VERSION ""

NS_ :

BS_:

BU_: Charger BMS

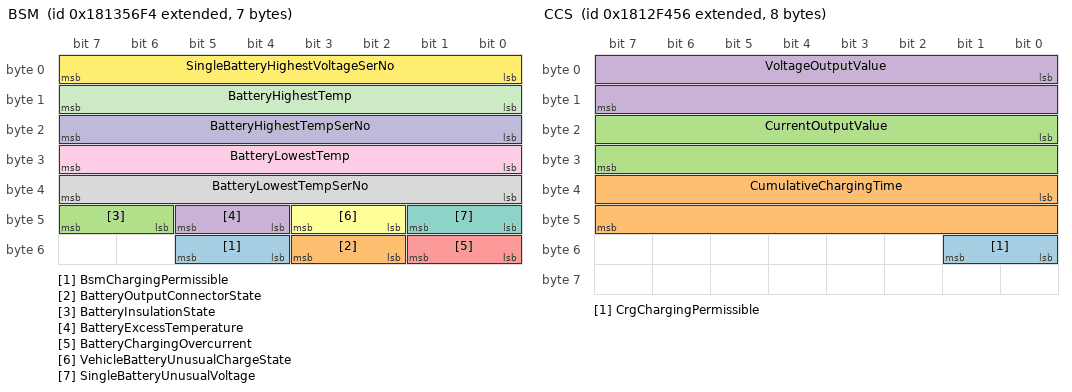
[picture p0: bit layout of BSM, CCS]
BO_ 2551404276 BSM: 7 BMS
 SG_ BsmChargingPermissible : 52|2@1+ (1,0) [0|3] ""  Charger
 SG_ BatteryOutputConnectorState : 50|2@1+ (1,0) [0|3] ""  Charger
 SG_ BatteryInsulationState : 46|2@1+ (1,0) [0|3] ""  Charger
 SG_ BatteryExcessTemperature : 44|2@1+ (1,0) [0|3] ""  Charger
 SG_ BatteryChargingOvercurrent : 48|2@1+ (1,0) [0|3] ""  Charger
 SG_ VehicleBatteryUnusualChargeState : 42|2@1+ (1,0) [0|3] ""  Charger
 SG_ SingleBatteryUnusualVoltage : 40|2@1+ (1,0) [0|3] ""  Charger
 SG_ BatteryLowestTempSerNo : 32|8@1+ (1,1) [1|256] ""  Charger
 SG_ BatteryLowestTemp : 24|8@1+ (1,-50) [-50|200] "°C"  Charger
 SG_ BatteryHighestTempSerNo : 16|8@1+ (1,1) [1|256] ""  Charger
 SG_ BatteryHighestTemp : 8|8@1+ (1,-50) [-50|200] "°C"  Charger
 SG_ SingleBatteryHighestVoltageSerNo : 0|8@1+ (1,1) [1|256] ""  Charger

BO_ 2551379030 CCS: 8 Charger
 SG_ CrgChargingPermissible : 48|2@1+ (1,0) [0|3] ""  BMS
 SG_ CumulativeChargingTime : 32|16@1+ (1,0) [0|600] "min"  BMS
 SG_ CurrentOutputValue : 16|16@1+ (0.1,-400) [-400|6153.5] "A"  BMS
 SG_ VoltageOutputValue : 0|16@1+ (0.1,0) [0|6553.5] "V"  BMS

BO_ 2618382068 BCS: 9 BMS
 SG_ EstimatedRemainingChargingTime : 56|16@1+ (1,0) [0|600] "min"  Charger
 SG_ CurrentChargeState : 48|8@1+ (1,0) [0|100] "%"  Charger
 SG_ SingleBatteryHighestVoltageGroup : 44|4@1+ (1,0) [0|15] ""  Charger
 SG_ SingleBatteryHighestVoltage : 32|12@1+ (0.01,0) [0|24] "V"  Charger
 SG_ MeasuredChargingCurrent : 16|16@1+ (0.1,-400) [-400|6153.5] "A"  Charger
 SG_ MeasuredChargingVoltage : 0|16@1+ (0.1,0) [0|6553.5] "V"  Charger

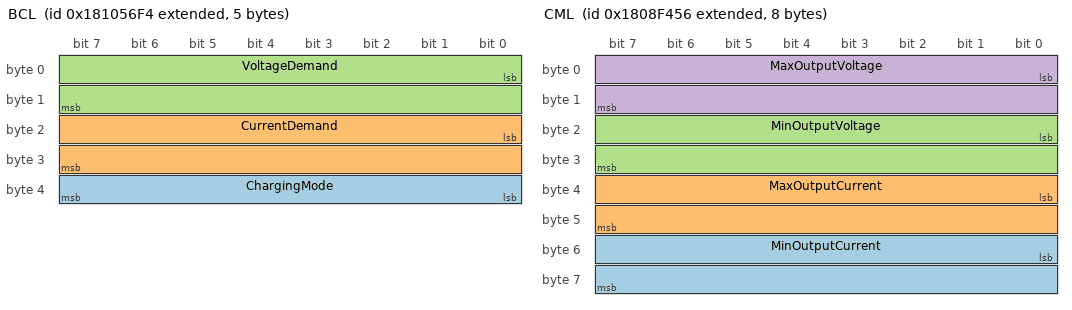
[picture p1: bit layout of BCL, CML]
BO_ 2551207668 BCL: 5 BMS
 SG_ ChargingMode : 32|8@1+ (1,0) [0|0] ""  Charger
 SG_ CurrentDemand : 16|16@1+ (0.1,-400) [-400|6153.5] "A"  Charger
 SG_ VoltageDemand : 0|16@1+ (0.1,0) [0|6553.5] "V"  Charger

BO_ 2416637014 CRO: 1 Charger
 SG_ ChargerReadyForCharging : 0|8@1+ (1,0) [0|255] ""  BMS

BO_ 2416531188 BRO: 1 BMS
 SG_ BmsReadyForCharging : 0|8@1+ (1,0) [0|255] ""  Charger

BO_ 2550723670 CML: 8 Charger
 SG_ MinOutputCurrent : 48|16@1+ (0.1,-400) [-400|6153.5] "A"  BMS
 SG_ MaxOutputCurrent : 32|16@1+ (0.1,-400) [-400|6153.5] "A"  BMS
 SG_ MinOutputVoltage : 16|16@1+ (0.1,0) [0|6553.5] "V"  BMS
 SG_ MaxOutputVoltage : 0|16@1+ (0.1,0) [0|6553.5] "V"  BMS

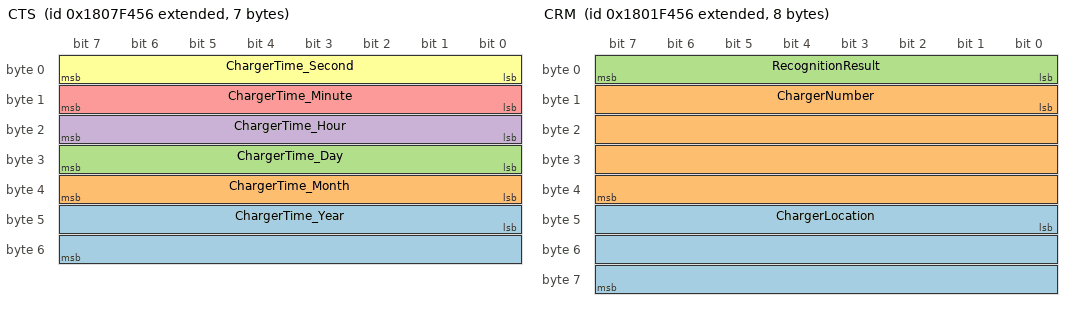
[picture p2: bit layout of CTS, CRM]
BO_ 2550658134 CTS: 7 Charger
 SG_ ChargerTime_Year : 40|16@1+ (1,0) [0|39321] ""  BMS
 SG_ ChargerTime_Month : 32|8@1+ (1,0) [0|18] ""  BMS
 SG_ ChargerTime_Day : 24|8@1+ (1,0) [0|49] ""  BMS
 SG_ ChargerTime_Hour : 16|8@1+ (1,0) [0|36] ""  BMS
 SG_ ChargerTime_Minute : 8|8@1+ (1,0) [0|96] ""  BMS
 SG_ ChargerTime_Second : 0|8@1+ (1,0) [0|96] ""  BMS

BO_ 2617661172 BCP: 13 BMS
 SG_ CurrentVehicleBatteryVoltage : 72|16@1+ (0.1,0) [0|6553.5] "V"  Charger
 SG_ StatusVehiclePowerStorageBattery : 88|16@1+ (0.1,0) [0|100] "%"  Charger
 SG_ MaxPermTemperature : 64|8@1+ (1,-50) [-50|200] "°C"  Charger
 SG_ TotalMaxPermChargingVoltage : 48|16@1+ (0.1,0) [0|6553.5] "V"  Charger
 SG_ TotalNominalEnergy : 32|16@1+ (0.1,0) [0|1000] "kWh"  Charger
 SG_ MaxPermChargingCurrent : 16|16@1+ (0.1,-400) [-400|6153.5] "A"  Charger
 SG_ MaxSingleBattChargingVoltage : 0|16@1+ (0.01,0) [0|24] "V"  Charger

BO_ 2617399028 BRM: 49 BMS
 SG_ BmsSoftwareVersion_Reserved : 368|24@1+ (1,0) [0|16777215] ""  Charger
 SG_ BmsSoftwareVersion_CompileYear : 352|16@1+ (1,0) [0|65534] ""  Charger
 SG_ BmsSoftwareVersion_CompileMonth : 344|8@1+ (1,0) [1|12] ""  Charger
 SG_ BmsSoftwareVersion_CompileDay : 336|8@1+ (1,0) [1|31] ""  Charger
 SG_ BmsSoftwareVersion_Serial : 328|8@1+ (1,0) [1|254] ""  Charger
 SG_ BRM_Reserved1 : 184|8@1+ (1,0) [0|255] ""  Charger
 SG_ VIN : 192|136@1+ (1,0) [0|0] ""  Charger
 SG_ Property : 176|8@1+ (1,0) [0|1] ""  Charger
 SG_ ChargingFrequency : 152|24@1+ (1,0) [0|16777215] ""  Charger
 SG_ ProductionDay : 144|8@1+ (1,0) [0|31] "Days"  Charger
 SG_ ProductionMonth : 136|8@1+ (1,0) [1|12] ""  Charger
 SG_ ProductionYear : 128|8@1+ (1,1985) [1985|2235] "Years"  Charger
 SG_ BatteryPackNumber : 96|32@1+ (1,0) [0|4294967295] ""  Charger
 SG_ ManufacturerName : 64|32@1+ (1,0) [0|4294967295] ""  Charger
 SG_ BatterySystemVoltage : 48|16@1+ (0.1,0) [0|6553.5] "V"  Charger
 SG_ BatterySystemCapacity : 32|16@1+ (0.1,0) [0|6553.5] "Ah"  Charger
 SG_ BmsVersion : 8|16@1+ (1,0) [0|65535] ""  Charger
 SG_ BmsRevision : 0|8@1+ (1,0) [0|255] ""  Charger
 SG_ BatteryType : 24|8@1+ (1,0) [0|255] ""  Charger

BO_ 2550264918 CRM: 8 Charger
 SG_ ChargerLocation : 40|24@1+ (1,0) [0|16777215] ""  BMS
 SG_ ChargerNumber : 8|32@1+ (1,0) [0|4294967295] ""  BMS
 SG_ RecognitionResult : 0|8@1+ (1,0) [0|170] ""  BMS

BO_ 2552714996 BHM: 2 BMS
 SG_ MaxChargingVoltage : 0|16@1+ (0.1,0) [0|6553.5] "V"  Charger

BO_ 2552689750 CHM: 3 Charger
 SG_ ChargerVersion : 8|16@1+ (1,0) [0|65535] ""  BMS
 SG_ ChargerRevision : 0|8@1+ (1,0) [0|255] ""  BMS

BO_ 2565603070 TPDT: 8 Vector__XXX
 SG_ SequenceNumber : 0|8@1+ (1,0) [0|255] "" Vector__XXX

BO_ 2565668606 TPCMxx: 8 Vector__XXX
 SG_ TotalNumberOfPacketsEoMA m19 : 24|8@1+ (1,0) [0|255] "" Vector__XXX
 SG_ TotalMessageSizeEoMA m19 : 8|16@1+ (1,0) [0|64255] "" Vector__XXX
 SG_ TotalMessageSizeBAM m32 : 8|16@1+ (1,0) [0|64255] "" Vector__XXX
 SG_ TotalNumberOfPacketsBAM m32 : 24|8@1+ (1,0) [0|255] "" Vector__XXX
 SG_ ConnectionAbortReason m255 : 8|8@1+ (1,0) [0|255] "" Vector__XXX
 SG_ NextPacketNumberToBeSent m17 : 16|8@1+ (1,0) [0|255] "" Vector__XXX
 SG_ NumberOfPacketsThatCanBeSent m17 : 8|8@1+ (1,0) [0|255] "" Vector__XXX
 SG_ PGNumber : 40|24@1+ (1,0) [0|16777200] "" Vector__XXX
 SG_ MaximumNumberOfPackets m16 : 32|8@1+ (1,0) [0|255] "" Vector__XXX
 SG_ TotalNumberOfPackets m16 : 24|8@1+ (1,0) [0|255] "" Vector__XXX
 SG_ TotalMessageSize m16 : 8|16@1+ (1,0) [0|64255] "" Vector__XXX
 SG_ ControlByte M : 0|8@1+ (1,0) [0|255] "" Vector__XXX

BO_ 2565537534 RQST: 3 Vector__XXX
 SG_ ParameterGroupNumber : 0|24@1+ (1,0) [0|16777215] "" Vector__XXX

BO_ 2565406462 ACKM: 8 Vector__XXX
 SG_ AddressBusy m3 : 32|8@1+ (1,0) [0|255] "" Vector__XXX
 SG_ ControlByte M : 0|8@1+ (1,0) [0|255] "" Vector__XXX
 SG_ ParameterGroupNumber : 40|24@1+ (1,0) [0|16777215] "" Vector__XXX
 SG_ GroupFunctionValue : 8|8@1+ (1,0) [0|255] "" Vector__XXX
 SG_ AddressAccessDenied m2 : 32|8@1+ (1,0) [0|255] "" Vector__XXX
 SG_ AddressNegativeAcknowledgement m1 : 32|8@1+ (1,0) [0|255] "" Vector__XXX
 SG_ AddressAcknowledged m0 : 32|8@1+ (1,0) [0|255] "" Vector__XXX

CM_ BO_ 2551404276 "Power storage battery status information";
CM_ SG_ 2551404276 BsmChargingPermissible "Charging permissible (<00>: = forbid ; <01>: = permit)";
CM_ SG_ 2551404276 BatteryOutputConnectorState "Connection state of output connector of power storage battery set (<00>: = normal; <01>: = abnormal; <10>: = untrusted state)";
CM_ SG_ 2551404276 BatteryInsulationState "Insulation state of power storage battery (<00>: = normal; <01>: = abnormal; <10>: = untrusted state)";
CM_ SG_ 2551404276 BatteryExcessTemperature "Excess temperature of power storage battery (<00>: = normal;<01>: =over-high;<10>: untrusted state)";
CM_ SG_ 2551404276 BatteryChargingOvercurrent "Charging overcurrent of power storage battery (<00>: = normal;<01>: =over-current;<10>: untrusted state)";
CM_ SG_ 2551404276 VehicleBatteryUnusualChargeState "State-of-charge SOC of power storage battery for complete vehicle is over-high/over-low (<00> : = normal; <01> : = over-high; <10> : = over-low)";
CM_ SG_ 2551404276 SingleBatteryUnusualVoltage "Voltage of single power storage battery is over-high/over-low (<00>: = normal; <01>: = over-high; <10>: = over-low)";
CM_ SG_ 2551404276 BatteryLowestTempSerNo "Serial number of the lowest temperature detection point of power storage battery";
CM_ SG_ 2551404276 BatteryLowestTemp "The lowest temperature of power storage battery";
CM_ SG_ 2551404276 BatteryHighestTempSerNo "Serial number of the highest temperature detection point";
CM_ SG_ 2551404276 BatteryHighestTemp "Highest temperature of power storage battery";
CM_ SG_ 2551404276 SingleBatteryHighestVoltageSerNo "Serial number of the highest voltage of single power storage battery";
CM_ BO_ 2551379030 "Charger's charging status";
CM_ SG_ 2551379030 CrgChargingPermissible "Charging permissible (<00>: = suspend; <01>: = permit)";
CM_ SG_ 2551379030 CumulativeChargingTime "Cumulative charging time (min)";
CM_ SG_ 2551379030 CurrentOutputValue "Current output value (A)";
CM_ SG_ 2551379030 VoltageOutputValue "Voltage output value (V)";
CM_ BO_ 2618382068 "Overall battery charging status";
CM_ SG_ 2618382068 EstimatedRemainingChargingTime "Estimated remaining charging time (min)";
CM_ SG_ 2618382068 CurrentChargeState "Current state-of-charge SOC (%)";
CM_ SG_ 2618382068 SingleBatteryHighestVoltageGroup "Highest voltage of single power battery and its group number

13~ 16 bits: group number in which the highest voltage of single power storage battery is located";
CM_ SG_ 2618382068 SingleBatteryHighestVoltage "Highest voltage of single power battery and its group number

1~  12  bits:  voltage  of  maximum  single  power  storage  battery";
CM_ SG_ 2618382068 MeasuredChargingCurrent "Measured value of charging current (A)";
CM_ SG_ 2618382068 MeasuredChargingVoltage "Measured value of charging voltage (V)";
CM_ BO_ 2551207668 "Battery charging demand";
CM_ SG_ 2551207668 ChargingMode "Charging mode (0x01: constant voltage charge; 0x02: constant current charge)";
CM_ SG_ 2551207668 CurrentDemand "Current demand (A)";
CM_ SG_ 2551207668 VoltageDemand "Voltage demand (V)";
CM_ BO_ 2416637014 "Charger output ready state";
CM_ SG_ 2416637014 ChargerReadyForCharging "Whether BMS is ready for charging (<0 x00>: = BMS is not ready for charging; < 0xAA>: = BMS has been ready for charging; <0xFF>: = invalid)";
CM_ BO_ 2416531188 "Battery charging ready state";
CM_ SG_ 2416531188 BmsReadyForCharging "Whether BMS is ready for charging (<0 x00>: = BMS is not ready for charging; < 0xAA>: = BMS has been ready for charging; <0xFF>: = invalid)";
CM_ BO_ 2550723670 "Charger's maximum output";
CM_ SG_ 2550723670 MinOutputCurrent "Minimum output current (A)";
CM_ SG_ 2550723670 MaxOutputCurrent "Maximum output current (A)";
CM_ SG_ 2550723670 MinOutputVoltage "Minimum output voltage (V)";
CM_ SG_ 2550723670 MaxOutputVoltage "Maximum output voltage (V)";
CM_ BO_ 2550658134 "Charger send-time synchronization information";
CM_ SG_ 2550658134 ChargerTime_Year "Year/month/day/h/min/s

No. 1 byte: second (compressed BCD code)";
CM_ SG_ 2550658134 ChargerTime_Month "Year/month/day/h/min/s

No. 5 byte: month (compressed BCD code)";
CM_ SG_ 2550658134 ChargerTime_Day "Year/month/day/h/min/s

No. 4 byte: day (compressed BCD code)";
CM_ SG_ 2550658134 ChargerTime_Hour "Year/month/day/h/min/s

No. 3 byte: hour (compressed BCD code)";
CM_ SG_ 2550658134 ChargerTime_Minute "Year/month/day/h/min/s

No. 2 byte: minute (compressed BCD code)";
CM_ SG_ 2550658134 ChargerTime_Second "Year/month/day/h/min/s

No. 1 byte: second (compressed BCD code)";
CM_ BO_ 2617661172 "Charging parameters of power storage battery";
CM_ SG_ 2617661172 CurrentVehicleBatteryVoltage "Current battery voltage of power storage battery for complete vehicle";
CM_ SG_ 2617661172 StatusVehiclePowerStorageBattery "Status-of-charge of power storage battery for complete vehicle";
CM_ SG_ 2617661172 MaxPermTemperature "Maximum permissible temperature";
CM_ SG_ 2617661172 TotalMaxPermChargingVoltage "Total maximum permissible charging voltage";
CM_ SG_ 2617661172 TotalNominalEnergy "Total nominal energy of power storage battery";
CM_ SG_ 2617661172 MaxPermChargingCurrent "Maximum permissible charging current";
CM_ SG_ 2617661172 MaxSingleBattChargingVoltage "Maximum permissible charging voltage of single power storage battery";
CM_ BO_ 2617399028 "BMS and vehicle identification message";
CM_ SG_ 2617399028 BmsSoftwareVersion_Reserved "BMS software version number 8byte represents current BMS version information, determined according to hexadecimal coding. In which, Byte8, byte7, byte6-000001H~FFFFFEH, reserved, fill in FFFFFFH";
CM_ SG_ 2617399028 BmsSoftwareVersion_CompileYear "BMS software version number, determined according to hexadecimal coding. In which, Byte5, Byte4 - 0001H~FFFEH represents compilation year (e.g. the year of 2015: fill in Byte5-DFH, byte4-07H)";
CM_ SG_ 2617399028 BmsSoftwareVersion_CompileMonth "BMS software version number, determined according to hexadecimal coding. In which, Byte3 - 01H~0CH represents compilation month (e.g. November: fill in Byte 3 0BH)";
CM_ SG_ 2617399028 BmsSoftwareVersion_CompileDay "BMS software version number, determined according to hexadecimal coding. In which, Byte2 - 01H~1FH represents compilation day (e.g. the 10the day: fill in Byte 2 0AH)";
CM_ SG_ 2617399028 BmsSoftwareVersion_Serial "BMS software version number, determined according to hexadecimal coding. In which, Byte1 - 01H~FEH represents edition serial number (e.g. 16: fill in Byte 1-10H)";
CM_ SG_ 2617399028 BRM_Reserved1 "Reserve";
CM_ SG_ 2617399028 VIN "Vehicle identification number (VIN)";
CM_ SG_ 2617399028 Property "Battery  set  property  right  mark  (<0>:  =  lease;  <1>: existing on vehicle)";
CM_ SG_ 2617399028 ChargingFrequency "Battery set charging frequency: 1 time/bit, offset of 0 times, which is subject to BMS statistics.";
CM_ SG_ 2617399028 ProductionDay "Battery  set  production  date:  days,  1  day/bit;  offset  of  0 day; data scope: the 1st day ~ the 31st day";
CM_ SG_ 2617399028 ProductionMonth "Battery set production date: months, 1 month/bit; offset of 0 month; data scope: January~December";
CM_ SG_ 2617399028 ProductionYear "Battery  set  production  date:  years,  1  year/bit;  offset  in 1985; data scope: 1985~2235";
CM_ SG_ 2617399028 BatteryPackNumber "Battery pack No., which is reserved and will be defined by the manufacturer";
CM_ SG_ 2617399028 ManufacturerName "Battery manufacturer name and standard ASCII code";
CM_ SG_ 2617399028 BatterySystemVoltage "Power storage battery system of whole vehicle, with rated total voltage/V, 0.1 V/bit; 0V offset";
CM_ SG_ 2617399028 BatterySystemCapacity "Power storage battery system of whole vehicle, with rated capacity/Ah, 0.1 Ah/bit; 0Ah offset";
CM_ SG_ 2617399028 BmsVersion "In this standard, as for the charger communication protocol version No., its current version is specified as V1.1 and is expressed as: byte3, byte2 -- 0001H";
CM_ SG_ 2617399028 BmsRevision "In this standard, as for the charger communication protocol version No., its current version is specified as V1.1 and is expressed as: byte 1 -- 01H";
CM_ SG_ 2617399028 BatteryType "Battery type";
CM_ BO_ 2550264918 "Charger recognition";
CM_ SG_ 2550264918 ChargerLocation "Charger/charging  station  location  code,  standard  ASCII code";
CM_ SG_ 2550264918 ChargerNumber "Charger No., 1/bit; 0 offset; data scope:0~0 xFFFFFFFF";
CM_ SG_ 2550264918 RecognitionResult "Recognition  result,  (<0x00>:=BMS not recognizable; <0xAA>:=BMS recognizable)";
CM_ BO_ 2552714996 "Vehicle handshake";
CM_ SG_ 2552714996 MaxChargingVoltage "Total maximum permissible charging voltage";
CM_ BO_ 2552689750 "Charger handshake";
CM_ SG_ 2552689750 ChargerVersion "In this standard, as for the charger communication protocol version No., its current version is specified as V1.1 and is expressed as: byte3, byte2 -- 0001H";
CM_ SG_ 2552689750 ChargerRevision "In this standard, as for the charger communication protocol version No., its current version is specified as V1.1 and is expressed as: byte 1 -- 01H";
CM_ BO_ 2565603070 "Transport Protocol - Data Transfer
Used for the transfer of data associated with Parameter Groups that have more than 8 bytes of data.";
CM_ SG_ 2565603070 SequenceNumber "Sequence Number (TP.DT)";
CM_ BO_ 2565668606 "Transport Protocol - Connection Mgmt
Used for the transfer of Parameter Groups that have 9 or more bytes of data.";
CM_ SG_ 2565668606 TotalNumberOfPacketsEoMA "Total number of packets received for RTS/CTS message.  Zero and one are not valid values.";
CM_ SG_ 2565668606 TotalMessageSizeEoMA "Total message size (in bytes) received for RTS/CTS message.  Messages shorter than 9 data bytes should be sent without utilizing the transport protocol.  Messages longer than 1785 can not use the RTS/CTS transport protocol.";
CM_ SG_ 2565668606 TotalMessageSizeBAM "Total message size (in bytes) for BAM  message.  Messages shorter than 9 data bytes should be sent without utilizing the transport protocol.  Messages longer than 1785 can not use the BAM transport protocol.";
CM_ SG_ 2565668606 TotalNumberOfPacketsBAM "Total number of packets for BAM message.  Zero and one are not valid values.";
CM_ SG_ 2565668606 ConnectionAbortReason "Reason for connection abort message.
1 Already in one or more connection managed sessions and cannot support another.
2 System resources were needed for another task so this connection managed session was terminated.
3 A timeout occurred and this ...";
CM_ SG_ 2565668606 NextPacketNumberToBeSent "Next Packet Number to be sent (TP.CM_CTS)";
CM_ SG_ 2565668606 NumberOfPacketsThatCanBeSent "Number of Packets that can be sent (TP.CM_CTS)";
CM_ SG_ 2565668606 PGNumber "Requested PGN in the TP.CM_RTS message";
CM_ SG_ 2565668606 MaximumNumberOfPackets "Maximum number of packets for RTS/CTS message.  zero through four are not allowed";
CM_ SG_ 2565668606 TotalNumberOfPackets "Total number of packets for RTS/CTS message.  Zero and one are not valid values.";
CM_ SG_ 2565668606 TotalMessageSize "Total message size (in bytes) for RTS/CTS message.  Messages shorter than 9 data bytes should be sent without utilizing the transport protocol.  Messages longer than 1785 can not use the RTS/CTS transport protocol.";
CM_ SG_ 2565668606 ControlByte "Control byte (I.e. Group Function) associated with the Transport Protocol - Connection Management (PGN 60,416)
16 (dec) - Request to Send
17 (dec) - Clear to Send
19 (dec) - End of Message ACK
32 (dec) - Broadcast Announce Message
255 (dec) - ...";
CM_ BO_ 2565537534 "Request
This message type, identified by the PGN, provides the capability to request information globally or from a specific destination.";
CM_ SG_ 2565537534 ParameterGroupNumber "Whenever it is necessary to identify a Parameter Group in the data field of a CAN data frame, it will be expressed in 24 bits.  The Parameter Group Number is a 24 bit value that has the following constituent components:  Reserved bit, Data Page bit, ...";
CM_ BO_ 2565406462 "Acknowledgment Message
The Acknowledgment PG is used to provide a handshake mechanism between transmitting and receiving devices.";
CM_ SG_ 2565406462 ControlByte "Indicates the acknowledgement response.
0 - Positive Acknowledgment (ACK)
1 - Negative Acknowledgment (NACK)
2 - Access Denied (PGN supported but access denied)
3 - Cannot Respond (PGN supported but ECU cannot respond now) cannot respond with ...";
CM_ SG_ 2565406462 ParameterGroupNumber "PGN which is requested by the Request message";
CM_ SG_ 2565406462 GroupFunctionValue "Group Function of PGN being acknowledged. This field identifies for a device the specific group function of a PGN being acknowledged or declined.  This field is not used if the PGN being acknowledged or declined is not a group function PGN.";
BA_DEF_ SG_  "SigType" ENUM  "Default","Range","RangeSigned","ASCII","Discrete","Control","ReferencePGN","DTC","StringDelimiter","StringLength","StringLengthControl","MessageCounter","MessageChecksum";
BA_DEF_ SG_  "GenSigStartValue" INT 0 2147483647;
BA_DEF_ SG_  "GenSigSendType" ENUM  "Cyclic","OnWrite","OnWriteWithRepetition","OnChange","OnChangeWithRepetition","IfActive","IfActiveWithRepetition","NoSigSendType";
BA_DEF_ SG_  "GenSigILSupport" ENUM  "No","Yes";
BA_DEF_ SG_  "GenSigEVName" STRING ;
BA_DEF_ SG_  "SPN" INT 0 524287;
BA_DEF_ BO_  "TpJ1939VarDlc" ENUM  "No","Yes";
BA_DEF_ BO_  "GenMsgILSupport" ENUM  "No","Yes";
BA_DEF_ BO_  "GenMsgRequestable" INT 0 1;
BA_DEF_ BO_  "GenMsgSendType" ENUM  "cyclic","NotUsed","NotUsed","NotUsed","NotUsed","NotUsed","NotUsed","IfActive","noMsgSendType";
BA_DEF_ BO_  "VFrameFormat" ENUM  "StandardCAN","ExtendedCAN","reserved","J1939PG";
BA_DEF_ BO_  "GenMsgCycleTime" INT 0 3600000;
BA_DEF_DEF_  "SigType" "Default";
BA_DEF_DEF_  "GenSigStartValue" 0;
BA_DEF_DEF_  "GenSigSendType" "NoSigSendType";
BA_DEF_DEF_  "GenSigILSupport" "Yes";
BA_DEF_DEF_  "GenSigEVName" "Env@Nodename_@Signame";
BA_DEF_DEF_  "SPN" 0;
BA_DEF_DEF_  "TpJ1939VarDlc" "No";
BA_DEF_DEF_  "GenMsgILSupport" "Yes";
BA_DEF_DEF_  "GenMsgRequestable" 1;
BA_DEF_DEF_  "GenMsgSendType" "noMsgSendType";
BA_DEF_DEF_  "VFrameFormat" "J1939PG";
BA_DEF_DEF_  "GenMsgCycleTime" 0;
BA_ "GenMsgILSupport" BO_ 2551404276 0;
BA_ "GenMsgRequestable" BO_ 2551404276 0;
BA_ "GenMsgSendType" BO_ 2551404276 0;
BA_ "GenMsgCycleTime" BO_ 2551404276 250;
BA_ "GenMsgILSupport" BO_ 2551379030 0;
BA_ "GenMsgRequestable" BO_ 2551379030 0;
BA_ "GenMsgSendType" BO_ 2551379030 0;
BA_ "GenMsgCycleTime" BO_ 2551379030 50;
BA_ "GenMsgILSupport" BO_ 2618382068 0;
BA_ "GenMsgRequestable" BO_ 2618382068 0;
BA_ "GenMsgSendType" BO_ 2618382068 0;
BA_ "GenMsgCycleTime" BO_ 2618382068 250;
BA_ "GenMsgILSupport" BO_ 2551207668 0;
BA_ "GenMsgRequestable" BO_ 2551207668 0;
BA_ "GenMsgSendType" BO_ 2551207668 0;
BA_ "GenMsgCycleTime" BO_ 2551207668 50;
BA_ "GenMsgILSupport" BO_ 2416637014 0;
BA_ "GenMsgRequestable" BO_ 2416637014 0;
BA_ "GenMsgSendType" BO_ 2416637014 0;
BA_ "GenMsgCycleTime" BO_ 2416637014 250;
BA_ "GenMsgILSupport" BO_ 2416531188 0;
BA_ "GenMsgRequestable" BO_ 2416531188 0;
BA_ "GenMsgSendType" BO_ 2416531188 0;
BA_ "GenMsgCycleTime" BO_ 2416531188 250;
BA_ "GenMsgILSupport" BO_ 2550723670 0;
BA_ "GenMsgRequestable" BO_ 2550723670 0;
BA_ "GenMsgSendType" BO_ 2550723670 0;
BA_ "GenMsgCycleTime" BO_ 2550723670 250;
BA_ "GenMsgILSupport" BO_ 2550658134 0;
BA_ "GenMsgRequestable" BO_ 2550658134 0;
BA_ "GenMsgSendType" BO_ 2550658134 0;
BA_ "GenMsgCycleTime" BO_ 2550658134 500;
BA_ "GenMsgILSupport" BO_ 2617661172 0;
BA_ "GenMsgRequestable" BO_ 2617661172 0;
BA_ "GenMsgSendType" BO_ 2617661172 0;
BA_ "GenMsgCycleTime" BO_ 2617661172 500;
BA_ "GenMsgILSupport" BO_ 2617399028 0;
BA_ "GenMsgRequestable" BO_ 2617399028 0;
BA_ "GenMsgSendType" BO_ 2617399028 0;
BA_ "GenMsgCycleTime" BO_ 2617399028 250;
BA_ "TpJ1939VarDlc" BO_ 2617399028 1;
BA_ "GenMsgILSupport" BO_ 2550264918 0;
BA_ "GenMsgRequestable" BO_ 2550264918 0;
BA_ "GenMsgSendType" BO_ 2550264918 0;
BA_ "GenMsgCycleTime" BO_ 2550264918 250;
BA_ "GenMsgILSupport" BO_ 2552714996 0;
BA_ "GenMsgRequestable" BO_ 2552714996 0;
BA_ "GenMsgSendType" BO_ 2552714996 0;
BA_ "GenMsgCycleTime" BO_ 2552714996 250;
BA_ "GenMsgILSupport" BO_ 2552689750 0;
BA_ "GenMsgRequestable" BO_ 2552689750 0;
BA_ "GenMsgSendType" BO_ 2552689750 0;
BA_ "GenMsgCycleTime" BO_ 2552689750 250;
BA_ "GenMsgRequestable" BO_ 2565603070 0;
BA_ "GenMsgILSupport" BO_ 2565603070 0;
BA_ "GenMsgRequestable" BO_ 2565668606 0;
BA_ "GenMsgILSupport" BO_ 2565668606 0;
BA_ "GenMsgRequestable" BO_ 2565537534 0;
BA_ "GenMsgILSupport" BO_ 2565537534 0;
BA_ "GenMsgRequestable" BO_ 2565406462 0;
BA_ "GenMsgILSupport" BO_ 2565406462 0;
BA_ "SPN" SG_ 2551404276 BsmChargingPermissible 3096;
BA_ "GenSigILSupport" SG_ 2551404276 BsmChargingPermissible 0;
BA_ "SigType" SG_ 2551404276 BsmChargingPermissible 4;
BA_ "SPN" SG_ 2551404276 BatteryOutputConnectorState 3095;
BA_ "GenSigILSupport" SG_ 2551404276 BatteryOutputConnectorState 0;
BA_ "SigType" SG_ 2551404276 BatteryOutputConnectorState 4;
BA_ "SPN" SG_ 2551404276 BatteryInsulationState 3094;
BA_ "GenSigILSupport" SG_ 2551404276 BatteryInsulationState 0;
BA_ "SigType" SG_ 2551404276 BatteryInsulationState 4;
BA_ "SPN" SG_ 2551404276 BatteryExcessTemperature 3093;
BA_ "GenSigILSupport" SG_ 2551404276 BatteryExcessTemperature 0;
BA_ "SigType" SG_ 2551404276 BatteryExcessTemperature 4;
BA_ "SPN" SG_ 2551404276 BatteryChargingOvercurrent 3092;
BA_ "GenSigILSupport" SG_ 2551404276 BatteryChargingOvercurrent 0;
BA_ "SigType" SG_ 2551404276 BatteryChargingOvercurrent 4;
BA_ "SPN" SG_ 2551404276 VehicleBatteryUnusualChargeState 3091;
BA_ "GenSigILSupport" SG_ 2551404276 VehicleBatteryUnusualChargeState 0;
BA_ "SigType" SG_ 2551404276 VehicleBatteryUnusualChargeState 4;
BA_ "SPN" SG_ 2551404276 SingleBatteryUnusualVoltage 3090;
BA_ "GenSigILSupport" SG_ 2551404276 SingleBatteryUnusualVoltage 0;
BA_ "SigType" SG_ 2551404276 SingleBatteryUnusualVoltage 4;
BA_ "SPN" SG_ 2551404276 BatteryLowestTempSerNo 3089;
BA_ "GenSigILSupport" SG_ 2551404276 BatteryLowestTempSerNo 0;
BA_ "SigType" SG_ 2551404276 BatteryLowestTempSerNo 1;
BA_ "SPN" SG_ 2551404276 BatteryLowestTemp 3088;
BA_ "GenSigILSupport" SG_ 2551404276 BatteryLowestTemp 0;
BA_ "GenSigStartValue" SG_ 2551404276 BatteryLowestTemp 50;
BA_ "SigType" SG_ 2551404276 BatteryLowestTemp 1;
BA_ "SPN" SG_ 2551404276 BatteryHighestTempSerNo 3087;
BA_ "GenSigILSupport" SG_ 2551404276 BatteryHighestTempSerNo 0;
BA_ "SigType" SG_ 2551404276 BatteryHighestTempSerNo 1;
BA_ "SPN" SG_ 2551404276 BatteryHighestTemp 3086;
BA_ "GenSigILSupport" SG_ 2551404276 BatteryHighestTemp 0;
BA_ "GenSigStartValue" SG_ 2551404276 BatteryHighestTemp 50;
BA_ "SigType" SG_ 2551404276 BatteryHighestTemp 1;
BA_ "SigType" SG_ 2551404276 SingleBatteryHighestVoltageSerNo 1;
BA_ "GenSigILSupport" SG_ 2551404276 SingleBatteryHighestVoltageSerNo 0;
BA_ "SPN" SG_ 2551404276 SingleBatteryHighestVoltageSerNo 3085;
BA_ "SPN" SG_ 2551379030 CrgChargingPermissible 3929;
BA_ "GenSigILSupport" SG_ 2551379030 CrgChargingPermissible 0;
BA_ "SigType" SG_ 2551379030 CrgChargingPermissible 4;
BA_ "SPN" SG_ 2551379030 CumulativeChargingTime 3083;
BA_ "GenSigILSupport" SG_ 2551379030 CumulativeChargingTime 0;
BA_ "SigType" SG_ 2551379030 CumulativeChargingTime 1;
BA_ "SPN" SG_ 2551379030 CurrentOutputValue 3082;
BA_ "GenSigILSupport" SG_ 2551379030 CurrentOutputValue 0;
BA_ "GenSigStartValue" SG_ 2551379030 CurrentOutputValue 4000;
BA_ "SigType" SG_ 2551379030 CurrentOutputValue 1;
BA_ "SigType" SG_ 2551379030 VoltageOutputValue 1;
BA_ "GenSigILSupport" SG_ 2551379030 VoltageOutputValue 0;
BA_ "SPN" SG_ 2551379030 VoltageOutputValue 3081;
BA_ "SigType" SG_ 2618382068 EstimatedRemainingChargingTime 1;
BA_ "GenSigILSupport" SG_ 2618382068 EstimatedRemainingChargingTime 0;
BA_ "SPN" SG_ 2618382068 EstimatedRemainingChargingTime 3079;
BA_ "SigType" SG_ 2618382068 CurrentChargeState 1;
BA_ "GenSigILSupport" SG_ 2618382068 CurrentChargeState 0;
BA_ "SPN" SG_ 2618382068 CurrentChargeState 3078;
BA_ "SigType" SG_ 2618382068 SingleBatteryHighestVoltageGroup 4;
BA_ "GenSigILSupport" SG_ 2618382068 SingleBatteryHighestVoltageGroup 0;
BA_ "SPN" SG_ 2618382068 SingleBatteryHighestVoltageGroup 3077;
BA_ "SigType" SG_ 2618382068 SingleBatteryHighestVoltage 1;
BA_ "GenSigILSupport" SG_ 2618382068 SingleBatteryHighestVoltage 0;
BA_ "SPN" SG_ 2618382068 SingleBatteryHighestVoltage 3077;
BA_ "SigType" SG_ 2618382068 MeasuredChargingCurrent 1;
BA_ "GenSigStartValue" SG_ 2618382068 MeasuredChargingCurrent 4000;
BA_ "GenSigILSupport" SG_ 2618382068 MeasuredChargingCurrent 0;
BA_ "SPN" SG_ 2618382068 MeasuredChargingCurrent 3076;
BA_ "SigType" SG_ 2618382068 MeasuredChargingVoltage 1;
BA_ "GenSigILSupport" SG_ 2618382068 MeasuredChargingVoltage 0;
BA_ "SPN" SG_ 2618382068 MeasuredChargingVoltage 3075;
BA_ "SigType" SG_ 2551207668 ChargingMode 4;
BA_ "GenSigILSupport" SG_ 2551207668 ChargingMode 0;
BA_ "SPN" SG_ 2551207668 ChargingMode 3074;
BA_ "GenSigStartValue" SG_ 2551207668 CurrentDemand 4000;
BA_ "SigType" SG_ 2551207668 CurrentDemand 1;
BA_ "GenSigILSupport" SG_ 2551207668 CurrentDemand 0;
BA_ "SPN" SG_ 2551207668 CurrentDemand 3073;
BA_ "SigType" SG_ 2551207668 VoltageDemand 1;
BA_ "GenSigILSupport" SG_ 2551207668 VoltageDemand 0;
BA_ "SPN" SG_ 2551207668 VoltageDemand 3072;
BA_ "SigType" SG_ 2416637014 ChargerReadyForCharging 4;
BA_ "GenSigILSupport" SG_ 2416637014 ChargerReadyForCharging 0;
BA_ "SPN" SG_ 2416637014 ChargerReadyForCharging 2830;
BA_ "SigType" SG_ 2416531188 BmsReadyForCharging 4;
BA_ "GenSigILSupport" SG_ 2416531188 BmsReadyForCharging 0;
BA_ "SPN" SG_ 2416531188 BmsReadyForCharging 2829;
BA_ "SigType" SG_ 2550723670 MinOutputCurrent 1;
BA_ "GenSigStartValue" SG_ 2550723670 MinOutputCurrent 4000;
BA_ "GenSigILSupport" SG_ 2550723670 MinOutputCurrent 0;
BA_ "SPN" SG_ 2550723670 MinOutputCurrent 2827;
BA_ "SigType" SG_ 2550723670 MaxOutputCurrent 1;
BA_ "GenSigILSupport" SG_ 2550723670 MaxOutputCurrent 0;
BA_ "SPN" SG_ 2550723670 MaxOutputCurrent 2826;
BA_ "GenSigStartValue" SG_ 2550723670 MaxOutputCurrent 4000;
BA_ "SigType" SG_ 2550723670 MinOutputVoltage 1;
BA_ "GenSigILSupport" SG_ 2550723670 MinOutputVoltage 0;
BA_ "SPN" SG_ 2550723670 MinOutputVoltage 2825;
BA_ "SigType" SG_ 2550723670 MaxOutputVoltage 1;
BA_ "GenSigILSupport" SG_ 2550723670 MaxOutputVoltage 0;
BA_ "SPN" SG_ 2550723670 MaxOutputVoltage 2824;
BA_ "GenSigILSupport" SG_ 2550658134 ChargerTime_Year 0;
BA_ "SPN" SG_ 2550658134 ChargerTime_Year 2823;
BA_ "GenSigILSupport" SG_ 2550658134 ChargerTime_Month 0;
BA_ "SPN" SG_ 2550658134 ChargerTime_Month 2823;
BA_ "GenSigILSupport" SG_ 2550658134 ChargerTime_Day 0;
BA_ "SPN" SG_ 2550658134 ChargerTime_Day 2823;
BA_ "GenSigILSupport" SG_ 2550658134 ChargerTime_Hour 0;
BA_ "SPN" SG_ 2550658134 ChargerTime_Hour 2823;
BA_ "GenSigILSupport" SG_ 2550658134 ChargerTime_Minute 0;
BA_ "SPN" SG_ 2550658134 ChargerTime_Minute 2823;
BA_ "GenSigILSupport" SG_ 2550658134 ChargerTime_Second 0;
BA_ "SPN" SG_ 2550658134 ChargerTime_Second 2823;
BA_ "SigType" SG_ 2617661172 StatusVehiclePowerStorageBattery 1;
BA_ "GenSigILSupport" SG_ 2617661172 StatusVehiclePowerStorageBattery 0;
BA_ "SPN" SG_ 2617661172 StatusVehiclePowerStorageBattery 2821;
BA_ "SigType" SG_ 2617661172 MaxPermTemperature 1;
BA_ "GenSigStartValue" SG_ 2617661172 MaxPermTemperature 50;
BA_ "GenSigILSupport" SG_ 2617661172 MaxPermTemperature 0;
BA_ "SPN" SG_ 2617661172 MaxPermTemperature 2820;
BA_ "SigType" SG_ 2617661172 TotalMaxPermChargingVoltage 1;
BA_ "GenSigILSupport" SG_ 2617661172 TotalMaxPermChargingVoltage 0;
BA_ "SPN" SG_ 2617661172 TotalMaxPermChargingVoltage 2819;
BA_ "SigType" SG_ 2617661172 TotalNominalEnergy 1;
BA_ "GenSigILSupport" SG_ 2617661172 TotalNominalEnergy 0;
BA_ "SPN" SG_ 2617661172 TotalNominalEnergy 2818;
BA_ "SigType" SG_ 2617661172 MaxPermChargingCurrent 1;
BA_ "GenSigStartValue" SG_ 2617661172 MaxPermChargingCurrent 4000;
BA_ "GenSigILSupport" SG_ 2617661172 MaxPermChargingCurrent 0;
BA_ "SPN" SG_ 2617661172 MaxPermChargingCurrent 2817;
BA_ "SigType" SG_ 2617661172 MaxSingleBattChargingVoltage 1;
BA_ "GenSigILSupport" SG_ 2617661172 MaxSingleBattChargingVoltage 0;
BA_ "SPN" SG_ 2617661172 MaxSingleBattChargingVoltage 2816;
BA_ "GenSigStartValue" SG_ 2617399028 BmsSoftwareVersion_Reserved 16777215;
BA_ "GenSigILSupport" SG_ 2617399028 BmsSoftwareVersion_Reserved 0;
BA_ "SPN" SG_ 2617399028 BmsSoftwareVersion_Reserved 2576;
BA_ "GenSigILSupport" SG_ 2617399028 BmsSoftwareVersion_CompileYear 0;
BA_ "SPN" SG_ 2617399028 BmsSoftwareVersion_CompileYear 2576;
BA_ "SigType" SG_ 2617399028 BmsSoftwareVersion_CompileYear 1;
BA_ "GenSigStartValue" SG_ 2617399028 BmsSoftwareVersion_CompileMonth 1;
BA_ "GenSigILSupport" SG_ 2617399028 BmsSoftwareVersion_CompileMonth 0;
BA_ "SPN" SG_ 2617399028 BmsSoftwareVersion_CompileMonth 2576;
BA_ "SigType" SG_ 2617399028 BmsSoftwareVersion_CompileMonth 4;
BA_ "GenSigStartValue" SG_ 2617399028 BmsSoftwareVersion_CompileDay 1;
BA_ "GenSigILSupport" SG_ 2617399028 BmsSoftwareVersion_CompileDay 0;
BA_ "SPN" SG_ 2617399028 BmsSoftwareVersion_CompileDay 2576;
BA_ "SigType" SG_ 2617399028 BmsSoftwareVersion_CompileDay 1;
BA_ "GenSigStartValue" SG_ 2617399028 BmsSoftwareVersion_Serial 1;
BA_ "GenSigILSupport" SG_ 2617399028 BmsSoftwareVersion_Serial 0;
BA_ "SPN" SG_ 2617399028 BmsSoftwareVersion_Serial 2576;
BA_ "SigType" SG_ 2617399028 BmsSoftwareVersion_Serial 1;
BA_ "GenSigStartValue" SG_ 2617399028 BRM_Reserved1 255;
BA_ "GenSigILSupport" SG_ 2617399028 BRM_Reserved1 0;
BA_ "SPN" SG_ 2617399028 BRM_Reserved1 2574;
BA_ "SigType" SG_ 2617399028 VIN 3;
BA_ "GenSigILSupport" SG_ 2617399028 VIN 0;
BA_ "SPN" SG_ 2617399028 VIN 2575;
BA_ "SigType" SG_ 2617399028 Property 4;
BA_ "SPN" SG_ 2617399028 Property 2573;
BA_ "GenSigILSupport" SG_ 2617399028 Property 0;
BA_ "SigType" SG_ 2617399028 ChargingFrequency 1;
BA_ "GenSigILSupport" SG_ 2617399028 ChargingFrequency 0;
BA_ "SPN" SG_ 2617399028 ChargingFrequency 2572;
BA_ "SigType" SG_ 2617399028 ProductionDay 1;
BA_ "GenSigILSupport" SG_ 2617399028 ProductionDay 0;
BA_ "SPN" SG_ 2617399028 ProductionDay 2571;
BA_ "GenSigILSupport" SG_ 2617399028 ProductionMonth 0;
BA_ "SPN" SG_ 2617399028 ProductionMonth 2571;
BA_ "SigType" SG_ 2617399028 ProductionMonth 4;
BA_ "GenSigStartValue" SG_ 2617399028 ProductionMonth 1;
BA_ "SigType" SG_ 2617399028 ProductionYear 1;
BA_ "GenSigILSupport" SG_ 2617399028 ProductionYear 0;
BA_ "SPN" SG_ 2617399028 ProductionYear 2571;
BA_ "SigType" SG_ 2617399028 BatteryPackNumber 1;
BA_ "GenSigILSupport" SG_ 2617399028 BatteryPackNumber 0;
BA_ "SPN" SG_ 2617399028 BatteryPackNumber 2570;
BA_ "GenSigILSupport" SG_ 2617399028 ManufacturerName 0;
BA_ "SPN" SG_ 2617399028 ManufacturerName 2569;
BA_ "SigType" SG_ 2617399028 ManufacturerName 3;
BA_ "GenSigILSupport" SG_ 2617399028 BatterySystemVoltage 0;
BA_ "SPN" SG_ 2617399028 BatterySystemVoltage 2568;
BA_ "SigType" SG_ 2617399028 BatterySystemVoltage 1;
BA_ "GenSigILSupport" SG_ 2617399028 BatterySystemCapacity 0;
BA_ "SPN" SG_ 2617399028 BatterySystemCapacity 2567;
BA_ "SigType" SG_ 2617399028 BatterySystemCapacity 1;
BA_ "GenSigILSupport" SG_ 2617399028 BmsVersion 0;
BA_ "SPN" SG_ 2617399028 BmsVersion 2565;
BA_ "SigType" SG_ 2617399028 BmsVersion 1;
BA_ "GenSigILSupport" SG_ 2617399028 BmsRevision 0;
BA_ "SPN" SG_ 2617399028 BmsRevision 2565;
BA_ "SigType" SG_ 2617399028 BmsRevision 1;
BA_ "GenSigILSupport" SG_ 2617399028 BatteryType 0;
BA_ "SPN" SG_ 2617399028 BatteryType 2566;
BA_ "SigType" SG_ 2617399028 BatteryType 4;
BA_ "GenSigILSupport" SG_ 2550264918 ChargerLocation 0;
BA_ "SPN" SG_ 2550264918 ChargerLocation 2562;
BA_ "SigType" SG_ 2550264918 ChargerLocation 3;
BA_ "GenSigILSupport" SG_ 2550264918 ChargerNumber 0;
BA_ "SPN" SG_ 2550264918 ChargerNumber 2561;
BA_ "SigType" SG_ 2550264918 ChargerNumber 1;
BA_ "GenSigILSupport" SG_ 2550264918 RecognitionResult 0;
BA_ "SPN" SG_ 2550264918 RecognitionResult 2560;
BA_ "SigType" SG_ 2550264918 RecognitionResult 4;
BA_ "SPN" SG_ 2552714996 MaxChargingVoltage 2601;
BA_ "GenSigILSupport" SG_ 2552714996 MaxChargingVoltage 0;
BA_ "SigType" SG_ 2552714996 MaxChargingVoltage 1;
BA_ "GenSigILSupport" SG_ 2552689750 ChargerVersion 0;
BA_ "SPN" SG_ 2552689750 ChargerVersion 2600;
BA_ "SigType" SG_ 2552689750 ChargerVersion 1;
BA_ "SPN" SG_ 2552689750 ChargerRevision 2600;
BA_ "GenSigILSupport" SG_ 2552689750 ChargerRevision 0;
BA_ "SigType" SG_ 2552689750 ChargerRevision 1;
BA_ "SPN" SG_ 2565603070 SequenceNumber 2572;
BA_ "GenSigILSupport" SG_ 2565603070 SequenceNumber 0;
BA_ "SPN" SG_ 2565668606 TotalNumberOfPacketsEoMA 2565;
BA_ "GenSigILSupport" SG_ 2565668606 TotalNumberOfPacketsEoMA 0;
BA_ "SigType" SG_ 2565668606 TotalMessageSizeEoMA 1;
BA_ "SPN" SG_ 2565668606 TotalMessageSizeEoMA 2564;
BA_ "GenSigILSupport" SG_ 2565668606 TotalMessageSizeEoMA 0;
BA_ "SigType" SG_ 2565668606 TotalMessageSizeBAM 1;
BA_ "SPN" SG_ 2565668606 TotalMessageSizeBAM 2567;
BA_ "GenSigILSupport" SG_ 2565668606 TotalMessageSizeBAM 0;
BA_ "SPN" SG_ 2565668606 TotalNumberOfPacketsBAM 2568;
BA_ "GenSigILSupport" SG_ 2565668606 TotalNumberOfPacketsBAM 0;
BA_ "SPN" SG_ 2565668606 ConnectionAbortReason 2570;
BA_ "GenSigILSupport" SG_ 2565668606 ConnectionAbortReason 0;
BA_ "SPN" SG_ 2565668606 NextPacketNumberToBeSent 2562;
BA_ "GenSigILSupport" SG_ 2565668606 NextPacketNumberToBeSent 0;
BA_ "SPN" SG_ 2565668606 NumberOfPacketsThatCanBeSent 2561;
BA_ "GenSigILSupport" SG_ 2565668606 NumberOfPacketsThatCanBeSent 0;
BA_ "SigType" SG_ 2565668606 PGNumber 6;
BA_ "SPN" SG_ 2565668606 PGNumber 2560;
BA_ "GenSigILSupport" SG_ 2565668606 PGNumber 0;
BA_ "SPN" SG_ 2565668606 MaximumNumberOfPackets 2559;
BA_ "GenSigILSupport" SG_ 2565668606 MaximumNumberOfPackets 0;
BA_ "SPN" SG_ 2565668606 TotalNumberOfPackets 2558;
BA_ "GenSigILSupport" SG_ 2565668606 TotalNumberOfPackets 0;
BA_ "SigType" SG_ 2565668606 TotalMessageSize 1;
BA_ "SPN" SG_ 2565668606 TotalMessageSize 2557;
BA_ "GenSigILSupport" SG_ 2565668606 TotalMessageSize 0;
BA_ "SPN" SG_ 2565668606 ControlByte 2556;
BA_ "GenSigILSupport" SG_ 2565668606 ControlByte 0;
BA_ "SigType" SG_ 2565537534 ParameterGroupNumber 6;
BA_ "SPN" SG_ 2565537534 ParameterGroupNumber 2540;
BA_ "GenSigILSupport" SG_ 2565537534 ParameterGroupNumber 0;
BA_ "SPN" SG_ 2565406462 AddressBusy 3293;
BA_ "GenSigILSupport" SG_ 2565406462 AddressBusy 0;
BA_ "SigType" SG_ 2565406462 ControlByte 6;
BA_ "SPN" SG_ 2565406462 ControlByte 2541;
BA_ "GenSigILSupport" SG_ 2565406462 ControlByte 0;
BA_ "SigType" SG_ 2565406462 ParameterGroupNumber 6;
BA_ "SPN" SG_ 2565406462 ParameterGroupNumber 2547;
BA_ "GenSigILSupport" SG_ 2565406462 ParameterGroupNumber 0;
BA_ "SigType" SG_ 2565406462 GroupFunctionValue 1;
BA_ "GenSigILSupport" SG_ 2565406462 GroupFunctionValue 0;
BA_ "SPN" SG_ 2565406462 GroupFunctionValue 2542;
BA_ "SPN" SG_ 2565406462 AddressAccessDenied 3292;
BA_ "GenSigILSupport" SG_ 2565406462 AddressAccessDenied 0;
BA_ "SPN" SG_ 2565406462 AddressNegativeAcknowledgement 3291;
BA_ "GenSigILSupport" SG_ 2565406462 AddressNegativeAcknowledgement 0;
BA_ "SPN" SG_ 2565406462 AddressAcknowledged 3290;
BA_ "GenSigILSupport" SG_ 2565406462 AddressAcknowledged 0;
VAL_ 2551404276 BsmChargingPermissible 3 "Not Available" 2 "Untrusted" 1 "Permit" 0 "Forbid" ;
VAL_ 2551404276 BatteryOutputConnectorState 3 "Not Available" 2 "Untrusted" 1 "Abnormal" 0 "Normal" ;
VAL_ 2551404276 BatteryInsulationState 3 "Not Available" 2 "Untrusted" 1 "Abnormal" 0 "Normal" ;
VAL_ 2551404276 BatteryExcessTemperature 3 "Not Available" 2 "Untrusted" 1 "Abnormal" 0 "Normal" ;
VAL_ 2551404276 BatteryChargingOvercurrent 3 "Not Available" 2 "Untrusted" 1 "Abnormal" 0 "Normal" ;
VAL_ 2551404276 VehicleBatteryUnusualChargeState 3 "Not Available" 2 "Over-Low" 1 "Over-High" 0 "Normal" ;
VAL_ 2551404276 SingleBatteryUnusualVoltage 3 "Not Available" 2 "Over-Low" 1 "Over-High" 0 "Normal" ;
VAL_ 2551379030 CrgChargingPermissible 3 "Not Available" 2 "Untrusted" 1 "Permit" 0 "Suspend" ;
VAL_ 2551207668 ChargingMode 2 "Constant Current" 1 "Constant Voltage" ;
VAL_ 2416637014 ChargerReadyForCharging 255 "Invalid" 170 "Ready" 0 "Not Ready" ;
VAL_ 2416531188 BmsReadyForCharging 255 "Invalid" 170 "Ready" 0 "Not Ready" ;
VAL_ 2617399028 BmsSoftwareVersion_CompileMonth 12 "December" 11 "November" 10 "October" 9 "September" 8 "August" 7 "July" 6 "June" 5 "May" 4 "April" 3 "March" 2 "February" 1 "January" ;
VAL_ 2617399028 Property 1 "Existing On Vehicle" 0 "Lease" ;
VAL_ 2617399028 ProductionMonth 12 "December" 11 "November" 10 "October" 9 "September" 8 "August" 7 "July" 6 "June" 5 "May" 4 "April" 3 "March" 2 "February" 1 "January" ;
VAL_ 2617399028 BatteryType 255 "Other Batteries" 8 "Lithium Ion Battery" 7 "Polymer Lithium-Ion Battery" 6 "Ternary Material Battery" 5 "Cobalt Based Lithium Battery" 4 "Lithium Manganate Battery" 3 "Lithium Iron Phosphate Battery" 2 "Nickel Hydrogen Battery" 1 "Lead Acid Battery" ;
VAL_ 2550264918 RecognitionResult 170 "BMS Recognizable" 0 "BMS Not Recognizable" ;
VAL_ 2565668606 ControlByte 255 "Abort" 32 "BAM" 19 "EoMA" 17 "CTS" 16 "RTS" ;
VAL_ 2565406462 ControlByte 3 "Cannot Respond" 2 "Access Denied" 1 "Negative Acknowledgment" 0 "Positive Acknowledgment" ;
